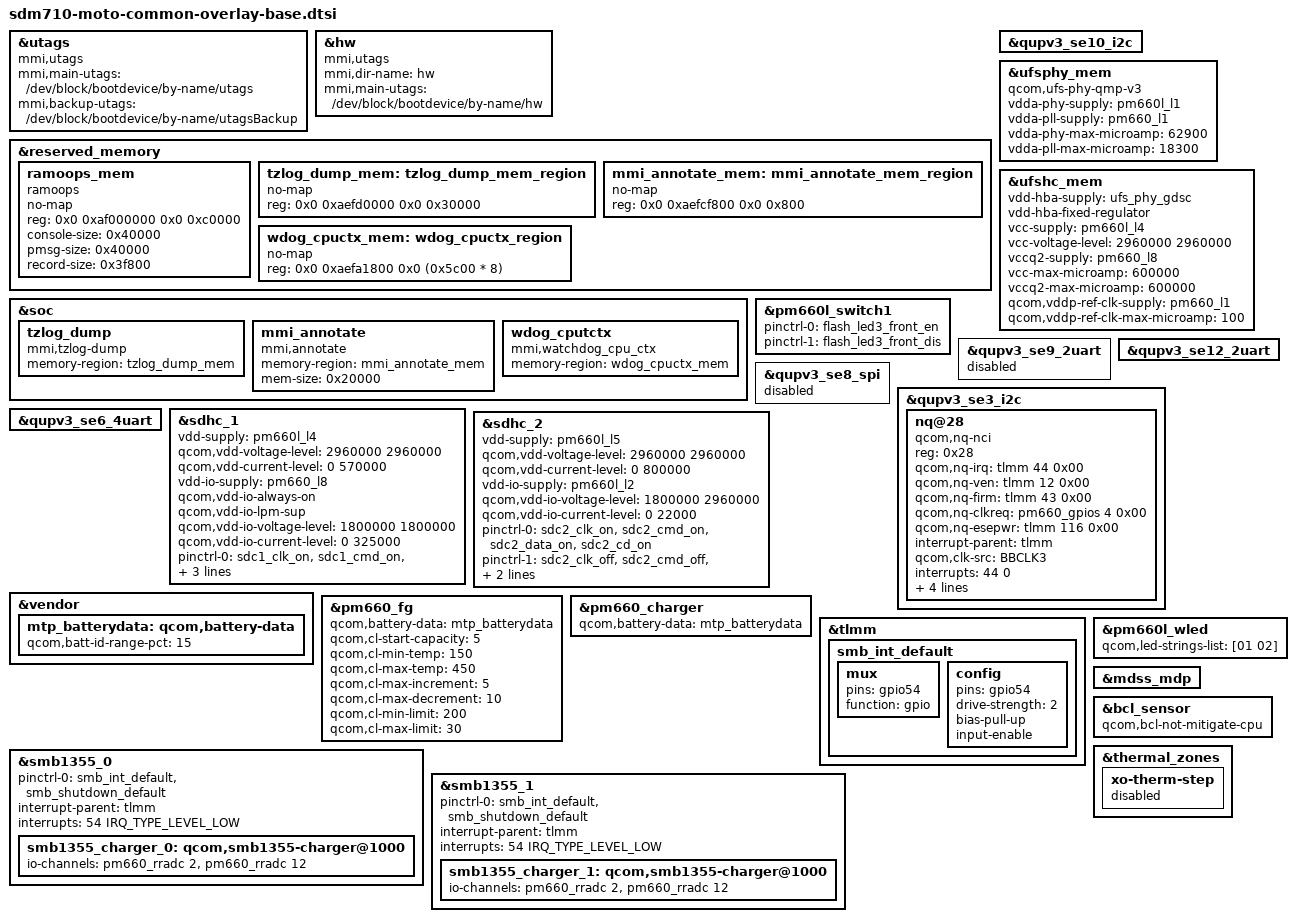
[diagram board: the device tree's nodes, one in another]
/* Copyright (c) 2017-2018, The Linux Foundation. All rights reserved.
 *
 * This program is free software; you can redistribute it and/or modify
 * it under the terms of the GNU General Public License version 2 and
 * only version 2 as published by the Free Software Foundation.
 *
 * This program is distributed in the hope that it will be useful,
 * but WITHOUT ANY WARRANTY; without even the implied warranty of
 * MERCHANTABILITY or FITNESS FOR A PARTICULAR PURPOSE.  See the
 * GNU General Public License for more details.
 */

#include <dt-bindings/gpio/gpio.h>
#include "sdm670-pmic-overlay.dtsi"
#include "sdm670-sde-display.dtsi"

&utags {
	compatible = "mmi,utags";
	mmi,main-utags = "/dev/block/bootdevice/by-name/utags";
	mmi,backup-utags = "/dev/block/bootdevice/by-name/utagsBackup";
};

&hw {
	compatible = "mmi,utags";
	mmi,dir-name = "hw";
	mmi,main-utags = "/dev/block/bootdevice/by-name/hw";
};

&reserved_memory {
	ramoops_mem {
		compatible = "ramoops";
		no-map;
		reg = <0x0 0xaf000000 0x0 0xc0000>;
		console-size = <0x40000>;
		pmsg-size = <0x40000>;
		record-size = <0x3f800>;
	};

	tzlog_dump_mem: tzlog_dump_mem_region {
		no-map;
		reg = <0x0 0xaefd0000 0x0 0x30000>;
	};

	mmi_annotate_mem: mmi_annotate_mem_region {
		no-map;
		reg = <0x0 0xaefcf800 0x0 0x800>;
	};

	wdog_cpuctx_mem: wdog_cpuctx_region {
		no-map;
		reg = <0x0 0xaefa1800 0x0 (0x5c00 * 8)>;
	};
};


&soc {
	tzlog_dump {
		compatible = "mmi,tzlog-dump";
		memory-region = <&tzlog_dump_mem>;
	};

	mmi_annotate {
		compatible = "mmi,annotate";
		memory-region = <&mmi_annotate_mem>;
		mem-size = <0x20000>;
	};

	wdog_cputctx {
		compatible = "mmi,watchdog_cpu_ctx";
		memory-region = <&wdog_cpuctx_mem>;
	};

};

&qupv3_se10_i2c {
#include "smb1355.dtsi"
};

&ufsphy_mem {
	compatible = "qcom,ufs-phy-qmp-v3";

	vdda-phy-supply = <&pm660l_l1>; /* 0.88v */
	vdda-pll-supply = <&pm660_l1>; /* 1.2v */
	vdda-phy-max-microamp = <62900>;
	vdda-pll-max-microamp = <18300>;

	status = "ok";
};

&ufshc_mem {
	vdd-hba-supply = <&ufs_phy_gdsc>;
	vdd-hba-fixed-regulator;
	vcc-supply = <&pm660l_l4>;
	vcc-voltage-level = <2960000 2960000>;
	vccq2-supply = <&pm660_l8>;
	vcc-max-microamp = <600000>;
	vccq2-max-microamp = <600000>;

	qcom,vddp-ref-clk-supply = <&pm660_l1>;
	qcom,vddp-ref-clk-max-microamp = <100>;

	status = "ok";
};

&pm660l_switch1 {
	pinctrl-names = "led_enable", "led_disable";
	pinctrl-0 = <&flash_led3_front_en>;
	pinctrl-1 = <&flash_led3_front_dis>;
};

&qupv3_se9_2uart {
	status = "disabled";
};

&qupv3_se12_2uart {
	status = "ok";
};

&qupv3_se8_spi {
	status = "disabled";
};

&qupv3_se3_i2c {
	status = "ok";
	nq@28 {
		compatible = "qcom,nq-nci";
		reg = <0x28>;
		qcom,nq-irq = <&tlmm 44 0x00>;
		qcom,nq-ven = <&tlmm 12 0x00>;
		qcom,nq-firm = <&tlmm 43 0x00>;
		qcom,nq-clkreq = <&pm660_gpios 4 0x00>;
		qcom,nq-esepwr = <&tlmm 116 0x00>;
		interrupt-parent = <&tlmm>;
		qcom,clk-src = "BBCLK3";
		interrupts = <44 0>;
		interrupt-names = "nfc_irq";
		pinctrl-names = "nfc_active", "nfc_suspend";
		pinctrl-0 = <&nfc_int_active
			     &nfc_enable_active
			     &nfc_clk_default>;
		pinctrl-1 = <&nfc_int_suspend &nfc_enable_suspend>;
		clocks = <&clock_rpmh RPMH_LN_BB_CLK3>;
		clock-names = "ref_clk";
	};
};

&qupv3_se10_i2c {
	status = "ok";
};

&qupv3_se6_4uart {
	status = "ok";
};

&sdhc_1 {
	vdd-supply = <&pm660l_l4>;
	qcom,vdd-voltage-level = <2960000 2960000>;
	qcom,vdd-current-level = <0 570000>;

	vdd-io-supply = <&pm660_l8>;
	qcom,vdd-io-always-on;
	qcom,vdd-io-lpm-sup;
	qcom,vdd-io-voltage-level = <1800000 1800000>;
	qcom,vdd-io-current-level = <0 325000>;

	pinctrl-names = "active", "sleep";
	pinctrl-0 = <&sdc1_clk_on  &sdc1_cmd_on &sdc1_data_on &sdc1_rclk_on>;
	pinctrl-1 = <&sdc1_clk_off &sdc1_cmd_off &sdc1_data_off &sdc1_rclk_off>;

	status = "ok";
};

&sdhc_2 {
	vdd-supply = <&pm660l_l5>;
	qcom,vdd-voltage-level = <2960000 2960000>;
	qcom,vdd-current-level = <0 800000>;

	vdd-io-supply = <&pm660l_l2>;
	qcom,vdd-io-voltage-level = <1800000 2960000>;
	qcom,vdd-io-current-level = <0 22000>;

	pinctrl-names = "active", "sleep";
	pinctrl-0 = <&sdc2_clk_on &sdc2_cmd_on &sdc2_data_on &sdc2_cd_on>;
	pinctrl-1 = <&sdc2_clk_off &sdc2_cmd_off &sdc2_data_off &sdc2_cd_off>;

	cd-gpios = <&tlmm 96 0x1>;

	status = "ok";
};

&vendor {
	mtp_batterydata: qcom,battery-data {
		qcom,batt-id-range-pct = <15>;
		#include "fg-gen3-batterydata-itech-3000mah.dtsi"
		#include "fg-gen3-batterydata-ascent-3450mah.dtsi"
		#include "fg-gen3-batterydata-demo-6000mah.dtsi"
	};
};

&pm660_fg {
	qcom,battery-data = <&mtp_batterydata>;
	qcom,cl-start-capacity = <5>;
	qcom,cl-min-temp = <150>;
	qcom,cl-max-temp = <450>;
	qcom,cl-max-increment = <5>;
	qcom,cl-max-decrement = <10>;
	qcom,cl-min-limit = <200>;
	qcom,cl-max-limit = <30>;
};

&pm660_charger {
	qcom,battery-data = <&mtp_batterydata>;
};

&tlmm {
	smb_int_default: smb_int_default {
		mux {
			pins = "gpio54";
			function = "gpio";
		};
		config {
			pins = "gpio54";
			drive-strength = <2>;
			bias-pull-up;
			input-enable;
		};
	};
};

&smb1355_0 {
	pinctrl-names = "default";
	pinctrl-0 = <&smb_int_default
			&smb_shutdown_default>;
	interrupt-parent = <&tlmm>;
	interrupts = <54 IRQ_TYPE_LEVEL_LOW>;
	smb1355_charger_0: qcom,smb1355-charger@1000 {
		io-channels = <&pm660_rradc 2>,
				<&pm660_rradc 12>;
		io-channel-names = "charger_temp",
				"charger_temp_max";
		status ="ok";
	};
};

&smb1355_1 {
	pinctrl-names = "default";
	pinctrl-0 = <&smb_int_default
			&smb_shutdown_default>;
	interrupt-parent = <&tlmm>;
	interrupts = <54 IRQ_TYPE_LEVEL_LOW>;
	smb1355_charger_1: qcom,smb1355-charger@1000 {
		io-channels = <&pm660_rradc 2>,
				<&pm660_rradc 12>;
		io-channel-names = "charger_temp",
				"charger_temp_max";
		status ="ok";
	};
};

&pm660l_wled {
	status = "okay";
	qcom,led-strings-list = [01 02];
};

&mdss_mdp {
	#cooling-cells = <2>;
};

&bcl_sensor {
	qcom,bcl-not-mitigate-cpu;
};

&thermal_zones {
	xo-therm-step {
		status = "disabled";
	};
};
